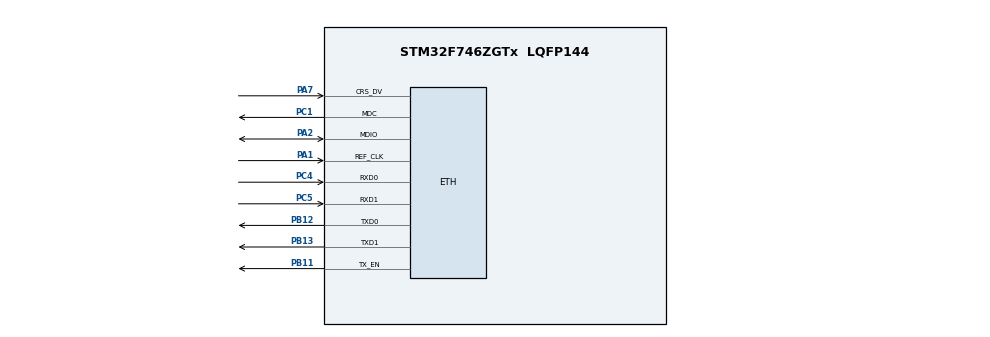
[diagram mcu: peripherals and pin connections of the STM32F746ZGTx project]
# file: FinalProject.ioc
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ETH.MediaInterface=HAL_ETH_RMII_MODE
LWIP.BSP.number=1
LWIP.IP_ADDRESS=192.168.007.002
LWIP.LWIP_DHCP=0
LWIP.NETMASK_ADDRESS=255.255.255.000
LWIP.Version=v2.1.2_Cube
LWIP0.BSP.STBoard=false
LWIP0.BSP.api=BSP_COMPONENT_DRIVER
LWIP0.BSP.component=LAN8742
LWIP0.BSP.instance=LAN8742
LWIP0.BSP.name=Driver_PHY
LWIP0.BSP.semaphore=S_LAN8742
LWIP0.BSP.solution=LAN8742
Mcu.Family=STM32F7
Mcu.Name=STM32F746ZGTx
Mcu.Package=LQFP144
NVIC.ETH_IRQn=true\:0\:0\:false\:false\:true\:true\:true\:true
NVIC.PriorityGroup=NVIC_PRIORITYGROUP_4
PA1.Mode=RMII
PA1.Signal=ETH_REF_CLK
PA2.Mode=RMII
PA2.Signal=ETH_MDIO
PA7.Mode=RMII
PA7.Signal=ETH_CRS_DV
PB11.Mode=RMII
PB11.Signal=ETH_TX_EN
PB12.Mode=RMII
PB12.Signal=ETH_TXD0
PB13.Mode=RMII
PB13.Signal=ETH_TXD1
PC1.Mode=RMII
PC1.Signal=ETH_MDC
PC4.Mode=RMII
PC4.Signal=ETH_RXD0
PC5.Mode=RMII
PC5.Signal=ETH_RXD1
ProjectManager.HeapSize=0x200
ProjectManager.StackSize=0x400
ProjectManager.TargetToolchain=STM32CubeIDE
RCC.HSE_VALUE=25000000
RCC.HSI_VALUE=16000000
RCC.LSE_VALUE=32768
RCC.USBFreq_Value=96000000
RCC.VCOOutputFreq_Value=192000000
VP_LWIP_VS_Enabled.Mode=Enabled
board=custom

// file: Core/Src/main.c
/* USER CODE BEGIN Header */
/**
  ******************************************************************************
  * @file           : main.c
  * @brief          : Main program body
  ******************************************************************************
  * @attention
  *
  * Copyright (c) 2024 STMicroelectronics.
  * All rights reserved.
  *
  * This software is licensed under terms that can be found in the LICENSE file
  * in the root directory of this software component.
  * If no LICENSE file comes with this software, it is provided AS-IS.
  *
  ******************************************************************************
  */
/* USER CODE END Header */
#include "main.h"
#include "lwip.h"
#include "Testing_Program.h"

void SystemClock_Config(void);
static void MX_GPIO_Init(void);

int main(void)
{

  /* MCU Configuration--------------------------------------------------------*/

  /* Reset of all peripherals, Initializes the Flash interface and the Systick. */
  HAL_Init();

  /* Configure the system clock */
  SystemClock_Config();

  /* Initialize all configured peripherals */
  MX_GPIO_Init();
  MX_LWIP_Init();

  /* Infinite loop */
  /* USER CODE BEGIN WHILE */
  while (1)
  {
	  Testing_Program();
    /* USER CODE END WHILE */

  }
}

void SystemClock_Config(void)
{
  RCC_OscInitTypeDef RCC_OscInitStruct = {0};
  RCC_ClkInitTypeDef RCC_ClkInitStruct = {0};

  /** Configure the main internal regulator output voltage
  */
  __HAL_RCC_PWR_CLK_ENABLE();
  __HAL_PWR_VOLTAGESCALING_CONFIG(PWR_REGULATOR_VOLTAGE_SCALE3);

  /** Initializes the RCC Oscillators according to the specified parameters
  * in the RCC_OscInitTypeDef structure.
  */
  RCC_OscInitStruct.OscillatorType = RCC_OSCILLATORTYPE_HSI;
  RCC_OscInitStruct.HSIState = RCC_HSI_ON;
  RCC_OscInitStruct.HSICalibrationValue = RCC_HSICALIBRATION_DEFAULT;
  RCC_OscInitStruct.PLL.PLLState = RCC_PLL_NONE;
  if (HAL_RCC_OscConfig(&RCC_OscInitStruct) != HAL_OK)
  {
    Error_Handler();
  }

  /** Initializes the CPU, AHB and APB buses clocks
  */
  RCC_ClkInitStruct.ClockType = RCC_CLOCKTYPE_HCLK|RCC_CLOCKTYPE_SYSCLK
                              |RCC_CLOCKTYPE_PCLK1|RCC_CLOCKTYPE_PCLK2;
  RCC_ClkInitStruct.SYSCLKSource = RCC_SYSCLKSOURCE_HSI;
  RCC_ClkInitStruct.AHBCLKDivider = RCC_SYSCLK_DIV1;
  RCC_ClkInitStruct.APB1CLKDivider = RCC_HCLK_DIV1;
  RCC_ClkInitStruct.APB2CLKDivider = RCC_HCLK_DIV1;

  if (HAL_RCC_ClockConfig(&RCC_ClkInitStruct, FLASH_LATENCY_0) != HAL_OK)
  {
    Error_Handler();
  }
}

static void MX_GPIO_Init(void)
{

  /* GPIO Ports Clock Enable */
  __HAL_RCC_GPIOC_CLK_ENABLE();
  __HAL_RCC_GPIOA_CLK_ENABLE();
  __HAL_RCC_GPIOB_CLK_ENABLE();

}

void Error_Handler(void)
{
  __disable_irq();
  while (1)
  {
  }
}
